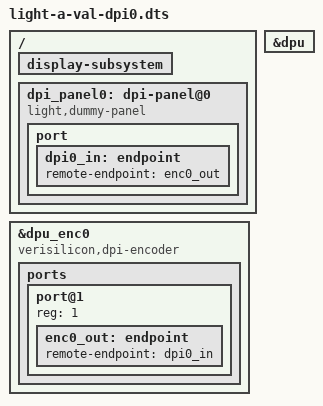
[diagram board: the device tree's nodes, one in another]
/* SPDX-License-Identifier: GPL-2.0 */
/*
 * Copyright (C) 2022 Alibaba Group Holding Limited.
 */

/dts-v1/;

#include "light-a-val.dts"

/ {
	display-subsystem {
		status = "okay";
	};

	dpi_panel0: dpi-panel@0 {
		compatible = "light,dummy-panel";

		port {
			dpi0_in: endpoint {
				remote-endpoint = <&enc0_out>;
			};
		};
	};
};

&dpu_enc0 {
	compatible = "verisilicon,dpi-encoder";
	status = "okay";

	ports {
		/* output */
		port@1 {
			reg = <1>;

			enc0_out: endpoint {
				remote-endpoint = <&dpi0_in>;
			};
		};
	};
};

&dpu {
	status = "okay";
};
